# EFR32FG23B021F512IM48 register map
Vendor: Silicon Labs; Series: EFR32; File version: C
CPU: CM33 r0p4, little endian, MPU, FPU, DSP, VTOR, 4 interrupt priority bits, 8 SAU regions
Registers are 32-bit, read-write, reset 0x0 unless marked. A register's access mark holds for its fields unless they carry their own. Offsets are from the block's base; [hi:lo] are bit positions; 'fields as' and 'values as' point back to an identical list.

## HFXO0_NS — HFXO0_NS Registers
Base 0x5A004000
Same registers: HFXO0_S 0x4A004000
0x00 IPVERSION ro reset 0x3
  [31:0] IPVERSION — IP Version ID
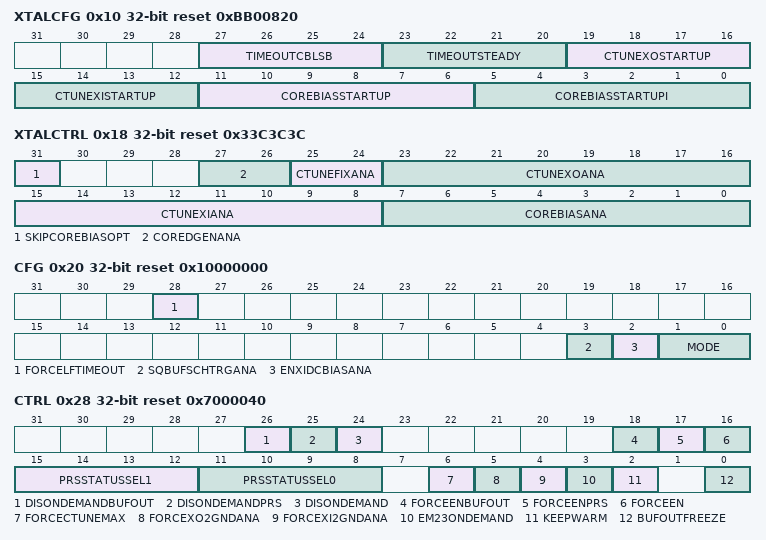
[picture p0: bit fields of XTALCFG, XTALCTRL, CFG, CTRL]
0x10 XTALCFG reset 0xBB00820
  [27:24] TIMEOUTCBLSB — Core Bias LSB Change Timeout
    0=T8US (The core bias LSB change timeout is set to 8 us minimum. The maximum can be +40%.); 1=T20US (The core bias LSB change timeout is set to 20 us minimum. The maximum can be +40%.); 2=T41US (The core bias LSB change timeout is set to 41 us minimum. The maximum can be +40%.); 3=T62US (The core bias LSB change timeout is set to 62 us minimum. The maximum can be +40%.); 4=T83US (The core bias LSB change timeout is set to 83 us minimum. The maximum can be +40%.); 5=T104US (The core bias LSB change timeout is set to 104 us minimum. The maximum can be +40%.); 6=T125US (The core bias LSB change timeout is set to 125 us minimum. The maximum can be +40%.); 7=T166US (The core bias LSB change timeout is set to 166 us minimum. The maximum can be +40%.); 8=T208US (The core bias LSB change timeout is set to 208 us minimum. The maximum can be +40%.); 9=T250US (The core bias LSB change timeout is set to 250 us minimum. The maximum can be +40%.); 10=T333US (The core bias LSB change timeout is set to 333 us minimum. The maximum can be +40%.); 11=T416US (The core bias LSB change timeout is set to 416 us minimum. The maximum can be +40%.); 12=T833US (The core bias LSB change timeout is set to 833 us minimum. The maximum can be +40%.); 13=T1250US (The core bias LSB change timeout is set to 1250 us minimum. The maximum can be +40%.); 14=T2083US (The core bias LSB change timeout is set to 2083 us minimum. The maximum can be +40%.); 15=T3750US (The core bias LSB change timeout is set to 3750 us minimum. The maximum can be +40%.)
  [23:20] TIMEOUTSTEADY — Steady State Timeout
    0=T4US (The steady state timeout is set to 16 us minimum. The maximum can be +40%.); 1=T16US (The steady state timeout is set to 41 us minimum. The maximum can be +40%.); 2=T41US (The steady state timeout is set to 83 us minimum. The maximum can be +40%.); 3=T83US (The steady state timeout is set to 125 us minimum. The maximum can be +40%.); 4=T125US (The steady state timeout is set to 166 us minimum. The maximum can be +40%.); 5=T166US (The steady state timeout is set to 208 us minimum. The maximum can be +40%.); 6=T208US (The steady state timeout is set to 250 us minimum. The maximum can be +40%.); 7=T250US (The steady state timeout is set to 333 us minimum. The maximum can be +40%.); 8=T333US (The steady state timeout is set to 416 us minimum. The maximum can be +40%.); 9=T416US (The steady state timeout is set to 500 us minimum. The maximum can be +40%.); 10=T500US (The steady state timeout is set to 666 us minimum. The maximum can be +40%.); 11=T666US (The steady state timeout is set to 833 us minimum. The maximum can be +40%.); 12=T833US (The steady state timeout is set to 1666 us minimum. The maximum can be +40%.); 13=T1666US (The steady state timeout is set to 2500 us minimum. The maximum can be +40%.); 14=T2500US (The steady state timeout is set to 4166 us minimum. The maximum can be +40%.); 15=T4166US (The steady state timeout is set to 7500 us minimum. The maximum can be +40%.)
  [19:16] CTUNEXOSTARTUP — Startup Tuning Capacitance on XO
  [15:12] CTUNEXISTARTUP — Startup Tuning Capacitance on XI
  [11:6] COREBIASSTARTUP — Startup Core Bias Current
  [5:0] COREBIASSTARTUPI — Intermediate Startup Core Bias Current
0x18 XTALCTRL reset 0x33C3C3C
  [31] SKIPCOREBIASOPT — Skip Core Bias Optimization
  [27:26] COREDGENANA — Core Degeneration
    0=NONE (Do not apply core degeneration resistence); 1=DGEN33 (Apply 33 ohm core degeneration resistence); 2=DGEN50 (Apply 50 ohm core degeneration resistence); 3=DGEN100 (Apply 100 ohm core degeneration resistence)
  [25:24] CTUNEFIXANA — Fixed Tuning Capacitance
    0=NONE (Remove fixed capacitance on XI and XO nodes); 1=XI (Adds fixed capacitance on XI node); 2=XO (Adds fixed capacitance on XO node); 3=BOTH (Adds fixed capacitance on both XI and XO nodes)
  [23:16] CTUNEXOANA — Tuning Capacitance on XO
  [15:8] CTUNEXIANA — Tuning Capacitance on XI
  [7:0] COREBIASANA — Core Bias Current
0x1C XTALCTRL1 reset 0x3C
  [7:0] CTUNEXIBUFOUTANA — BUFOUT Tuning Capacitance on XI
0x20 CFG reset 0x10000000
  [28] FORCELFTIMEOUT — Force Low Frequency Timeout
  [3] SQBUFSCHTRGANA — Squaring Buffer Schmitt Trigger
    0=DISABLE (Squaring buffer schmitt trigger is disabled); 1=ENABLE (Squaring buffer schmitt trigger is enabled)
  [2] ENXIDCBIASANA — Enable XI Internal DC Bias
  [1:0] MODE — Crystal Oscillator Mode
    0=XTAL (crystal oscillator); 1=EXTCLK (external sinusoidal clock can be supplied on XI pin.); 2=EXTCLKPKDET (external sinusoidal clock can be supplied on XI pin (peak detector used).)
0x28 CTRL reset 0x7000040
  [26] DISONDEMANDBUFOUT — Disable On-demand For BUFOUT
  [25] DISONDEMANDPRS — Disable On-demand For PRS
  [24] DISONDEMAND — Disable On-demand For Digital Clock
  [18] FORCEENBUFOUT — Force BUFOUT Request
  [17] FORCEENPRS — Force PRS Oscillator Request
  [16] FORCEEN — Force Digital Clock Request
  [15:12] PRSSTATUSSEL1 — PRS Status 1 Output Select
    0=DISABLED (PRS mux outputs 0); 1=ENS (PRS mux outputs enabled status); 2=COREBIASOPTRDY (PRS mux outputs core bias optimization ready status); 3=RDY (PRS mux outputs ready status); 4=PRSRDY (PRS mux outputs PRS ready status); 5=BUFOUTRDY (PRS mux outputs BUFOUT ready status); 8=HWREQ (PRS mux outputs oscillator requested by digital clock status); 9=PRSHWREQ (PRS mux outputs oscillator requested by PRS request status); 10=BUFOUTHWREQ (PRS mux outputs oscillator requested by BUFOUT request status)
  [11:8] PRSSTATUSSEL0 — PRS Status 0 Output Select
    values as PRSSTATUSSEL1
  [6] FORCECTUNEMAX — Force Tuning Cap to Max Value
  [5] FORCEXO2GNDANA — Force XO Pin to Ground
    0=DISABLE (Disabled (not pulled)); 1=ENABLE (Enabled (pulled))
  [4] FORCEXI2GNDANA — Force XI Pin to Ground
    values as FORCEXO2GNDANA
  [3] EM23ONDEMAND — On-demand During EM23
  [2] KEEPWARM
  [0] BUFOUTFREEZE — Freeze BUFOUT Controls
0x40 BUFOUTTRIM reset 0x8
  [3:0] VTRTRIMANA — BUFOUT Reference Trim
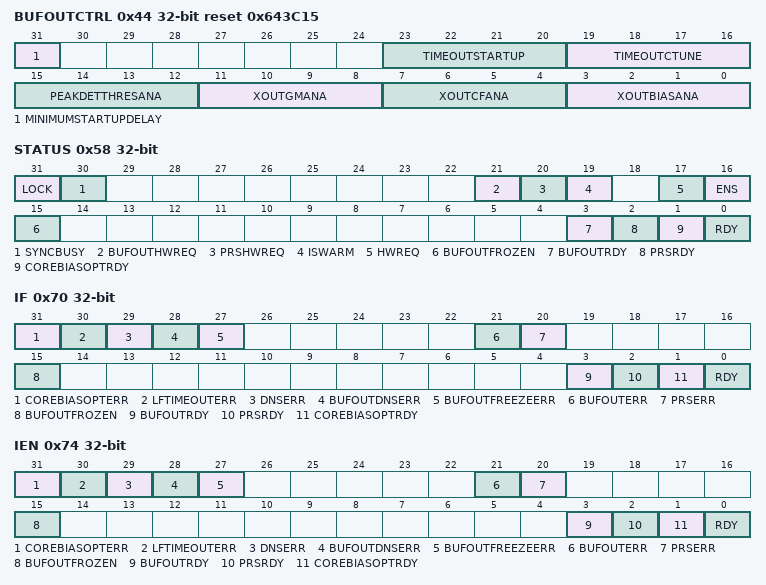
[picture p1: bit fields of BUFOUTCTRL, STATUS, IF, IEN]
0x44 BUFOUTCTRL reset 0x643C15
  [31] MINIMUMSTARTUPDELAY
  [23:20] TIMEOUTSTARTUP — Oscillator Startup Timeout
    0=T42US (The oscillator startup timeout is set to 42 us minimum. The maximum can be +40%.); 1=T83US (The oscillator startup timeout is set to 83 us minimum. The maximum can be +40%.); 2=T108US (The oscillator startup timeout is set to 108 us minimum. The maximum can be +40%.); 3=T133US (The oscillator startup timeout is set to 133 us minimum. The maximum can be +40%.); 4=T158US (The oscillator startup timeout is set to 158 us minimum. The maximum can be +40%.); 5=T183US (The oscillator startup timeout is set to 183 us minimum. The maximum can be +40%.); 6=T208US (The oscillator startup timeout is set to 208 us minimum. The maximum can be +40%.); 7=T233US (The oscillator startup timeout is set to 233 us minimum. The maximum can be +40%.); 8=T258US (The oscillator startup timeout is set to 258 us minimum. The maximum can be +40%.); 9=T283US (The oscillator startup timeout is set to 283 us minimum. The maximum can be +40%.); 10=T333US (The oscillator startup timeout is set to 333 us minimum. The maximum can be +40%.); 11=T375US (The oscillator startup timeout is set to 375 us minimum. The maximum can be +40%.); 12=T417US (The oscillator startup timeout is set to 417 us minimum. The maximum can be +40%.); 13=T458US (The oscillator startup timeout is set to 458 us minimum. The maximum can be +40%.); 14=T500US (The oscillator startup timeout is set to 500 us minimum. The maximum can be +40%.); 15=T667US (The oscillator startup timeout is set to 667 us minimum. The maximum can be +40%.)
  [19:16] TIMEOUTCTUNE — Tuning Cap Change Timeout
    0=T2US (The tuning cap change timeout is set to 2 us minimum. The maximum can be +40%.); 1=T5US (The tuning cap change timeout is set to 5 us minimum. The maximum can be +40%.); 2=T10US (The tuning cap change timeout is set to 10 us minimum. The maximum can be +40%.); 3=T16US (The tuning cap change timeout is set to 16 us minimum. The maximum can be +40%.); 4=T21US (The tuning cap change timeout is set to 21 us minimum. The maximum can be +40%.); 5=T26US (The tuning cap change timeout is set to 26 us minimum. The maximum can be +40%.); 6=T31US (The tuning cap change timeout is set to 31 us minimum. The maximum can be +40%.); 7=T42US (The tuning cap change timeout is set to 42 us minimum. The maximum can be +40%.); 8=T52US (The tuning cap change timeout is set to 52 us minimum. The maximum can be +40%.); 9=T63US (The tuning cap change timeout is set to 63 us minimum. The maximum can be +40%.); 10=T83US (The tuning cap change timeout is set to 83 us minimum. The maximum can be +40%.); 11=T104US (The tuning cap change timeout is set to 104 us minimum. The maximum can be +40%.); 12=T208US (The tuning cap change timeout is set to 208 us minimum. The maximum can be +40%.); 13=T313US (The tuning cap change timeout is set to 313 us minimum. The maximum can be +40%.); 14=T521US (The tuning cap change timeout is set to 521 us minimum. The maximum can be +40%.); 15=T938US (The tuning cap change timeout is set to 938 us minimum. The maximum can be +40%.)
  [15:12] PEAKDETTHRESANA — Peak Detector Threshold for XOUT
    0=V105MV; 1=V132MV; 2=V157MV; 3=V184MV; 4=V210MV; 5=V236MV; 6=V262MV; 7=V289MV; 8=V315MV; 9=V341MV; 10=V367MV; 11=V394MV; 12=V420MV; 13=V446MV; 14=V472MV; 15=V499MV
  [11:8] XOUTGMANA
  [7:4] XOUTCFANA — Buffer Gain
  [3:0] XOUTBIASANA — Driver Bias Current
0x50 CMD wo
  [0] COREBIASOPT — Core Bias Optimizaton
0x58 STATUS ro
  [31] LOCK — Configuration Lock Status
    0=UNLOCKED (Configuration lock is unlocked); 1=LOCKED (Configuration lock is locked)
  [30] SYNCBUSY
  [21] BUFOUTHWREQ — Oscillator Requested by BUFOUT Request
  [20] PRSHWREQ — Oscillator Requested by PRS Request
  [19] ISWARM — Oscillator Is Kept Warm
  [17] HWREQ — Oscillator Requested by Digital Clock
  [16] ENS — Enabled Status
  [15] BUFOUTFROZEN
  [3] BUFOUTRDY — BUFOUT Ready Status
  [2] PRSRDY — PRS Ready Status
  [1] COREBIASOPTRDY — Core Bias Optimization Ready
  [0] RDY — Ready Status
0x70 IF
  [31] COREBIASOPTERR — Core Bias Optimization Error Interrupt
  [30] LFTIMEOUTERR — Low Frequency Timeout Error Interrupt
  [29] DNSERR — Did Not Start Error Interrupt
  [28] BUFOUTDNSERR — BUFOUT Did Not Start Error Interrupt
  [27] BUFOUTFREEZEERR — BUFOUT Freeze Error Interrupt
  [21] BUFOUTERR — BUFOUT Request Error Interrupt
  [20] PRSERR — PRS Requset Error Interrupt
  [15] BUFOUTFROZEN — BUFOUT FROZEN Interrupt
  [3] BUFOUTRDY — BUFOUT Ready Interrupt
  [2] PRSRDY — PRS Ready Interrupt
  [1] COREBIASOPTRDY — Core Bias Optimization Ready Interrupt
  [0] RDY — Digital Clock Ready Interrupt
0x74 IEN
  fields as IF
0x80 LOCK wo reset 0x580E
  [15:0] LOCKKEY — Configuration Lock Key
    0x580E=UNLOCK (Write this value to unlock)
